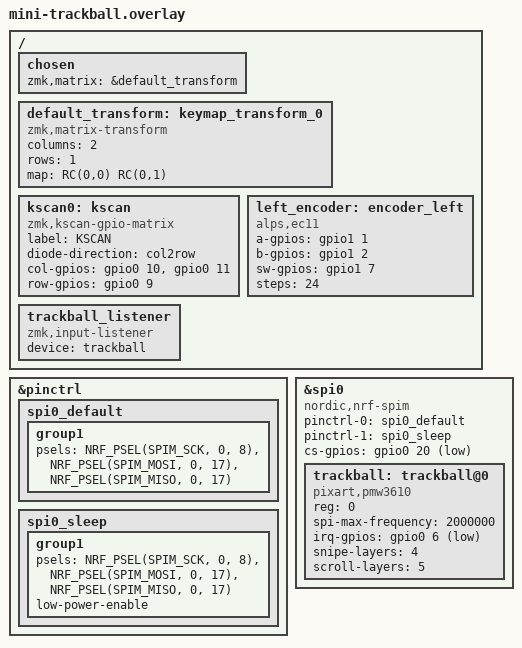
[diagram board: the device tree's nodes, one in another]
/*
 * Copyright (c) 2024 The ZMK Contributors
 *
 * SPDX-License-Identifier: MIT
 */

/ {
    chosen {
        zmk,matrix = &default_transform;
    };

    default_transform: keymap_transform_0 {
        compatible = "zmk,matrix-transform";
        columns = <2>;
        rows = <1>;
        map = <
            RC(0,0) RC(0,1)
        >;
    };

    kscan0: kscan {
        compatible = "zmk,kscan-gpio-matrix";
        label = "KSCAN";
        diode-direction = "col2row";
        col-gpios
            = <&gpio0 10 GPIO_ACTIVE_HIGH> // P0.10 (D16) for Col 0
            , <&gpio0 11 GPIO_ACTIVE_HIGH> // P0.11 (D7) for Col 1
            ;
        row-gpios
            = <&gpio0 9 (GPIO_ACTIVE_HIGH | GPIO_PULL_DOWN)> // P0.09 (D10) for Row 0
            ;
    };

    left_encoder: encoder_left {
        compatible = "alps,ec11";
        a-gpios = <&gpio1 1 (GPIO_ACTIVE_HIGH | GPIO_PULL_UP)>; // P1.01 for Encoder A
        b-gpios = <&gpio1 2 (GPIO_ACTIVE_HIGH | GPIO_PULL_UP)>; // P1.02 for Encoder B
        sw-gpios = <&gpio1 7 (GPIO_ACTIVE_HIGH | GPIO_PULL_UP)>; // P1.07 for Encoder SW
        steps = <24>;
        status = "okay";
    };
};

&pinctrl {
    spi0_default: spi0_default {
        group1 {
            psels = <NRF_PSEL(SPIM_SCK, 0, 8)>,  // P0.08 for SCK
                    <NRF_PSEL(SPIM_MOSI, 0, 17)>, // P0.17 for MOSI
                    <NRF_PSEL(SPIM_MISO, 0, 17)>; // P0.17 for MISO (shared with MOSI)
        };
    };

    spi0_sleep: spi0_sleep {
        group1 {
            psels = <NRF_PSEL(SPIM_SCK, 0, 8)>,
                    <NRF_PSEL(SPIM_MOSI, 0, 17)>,
                    <NRF_PSEL(SPIM_MISO, 0, 17)>;
            low-power-enable;
        };
    };
};

&spi0 {
    status = "okay";
    compatible = "nordic,nrf-spim";
    pinctrl-0 = <&spi0_default>;
    pinctrl-1 = <&spi0_sleep>;
    pinctrl-names = "default", "sleep";
    cs-gpios = <&gpio0 20 GPIO_ACTIVE_LOW>; // P0.20 (D3) for CS

    trackball: trackball@0 {
        status = "okay";
        compatible = "pixart,pmw3610";
        reg = <0>;
        spi-max-frequency = <2000000>;
        irq-gpios = <&gpio0 6 (GPIO_ACTIVE_LOW | GPIO_PULL_UP)>; // P0.06 (D1) for DR/MOTION

        /*   optional features   */
        snipe-layers = <4>;
        scroll-layers = <5>;
        /* automouse-layer = <4>; */
    };
};

/ {
  trackball_listener {
    compatible = "zmk,input-listener";
    device = <&trackball>;
  };
}; 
